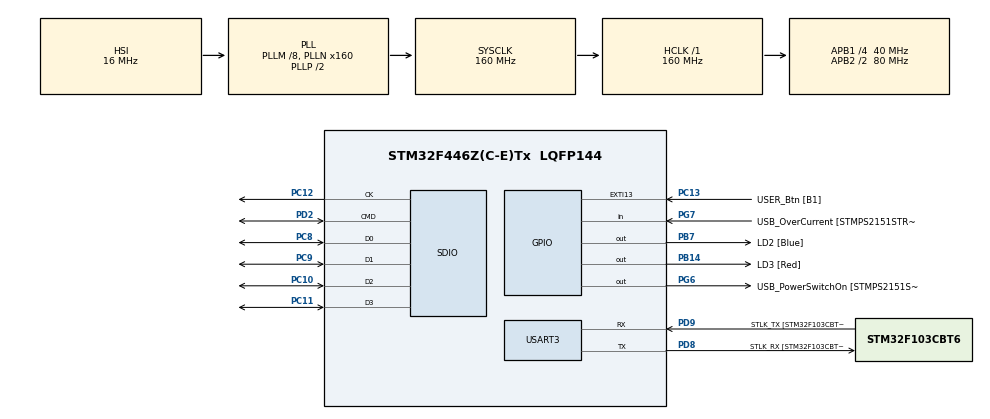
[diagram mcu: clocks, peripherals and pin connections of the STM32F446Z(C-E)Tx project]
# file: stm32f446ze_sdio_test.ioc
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Dma.Request0=SDIO_RX
Dma.Request1=SDIO_TX
Dma.SDIO_RX.0.Direction=DMA_PERIPH_TO_MEMORY
Dma.SDIO_RX.0.FIFOMode=DMA_FIFOMODE_ENABLE
Dma.SDIO_RX.0.FIFOThreshold=DMA_FIFO_THRESHOLD_FULL
Dma.SDIO_RX.0.Instance=DMA2_Stream3
Dma.SDIO_RX.0.MemBurst=DMA_MBURST_INC4
Dma.SDIO_RX.0.MemDataAlignment=DMA_MDATAALIGN_WORD
Dma.SDIO_RX.0.MemInc=DMA_MINC_ENABLE
Dma.SDIO_RX.0.Mode=DMA_PFCTRL
Dma.SDIO_RX.0.PeriphBurst=DMA_PBURST_INC4
Dma.SDIO_RX.0.PeriphDataAlignment=DMA_PDATAALIGN_WORD
Dma.SDIO_RX.0.PeriphInc=DMA_PINC_DISABLE
Dma.SDIO_RX.0.Priority=DMA_PRIORITY_LOW
Dma.SDIO_TX.1.Direction=DMA_MEMORY_TO_PERIPH
Dma.SDIO_TX.1.FIFOMode=DMA_FIFOMODE_ENABLE
Dma.SDIO_TX.1.FIFOThreshold=DMA_FIFO_THRESHOLD_FULL
Dma.SDIO_TX.1.Instance=DMA2_Stream6
Dma.SDIO_TX.1.MemBurst=DMA_MBURST_INC4
Dma.SDIO_TX.1.MemDataAlignment=DMA_MDATAALIGN_WORD
Dma.SDIO_TX.1.MemInc=DMA_MINC_ENABLE
Dma.SDIO_TX.1.Mode=DMA_PFCTRL
Dma.SDIO_TX.1.PeriphBurst=DMA_PBURST_INC4
Dma.SDIO_TX.1.PeriphDataAlignment=DMA_PDATAALIGN_WORD
Dma.SDIO_TX.1.PeriphInc=DMA_PINC_DISABLE
Dma.SDIO_TX.1.Priority=DMA_PRIORITY_LOW
Mcu.Family=STM32F4
Mcu.Name=STM32F446Z(C-E)Tx
Mcu.Package=LQFP144
NVIC.DMA2_Stream3_IRQn=true\:0\:0\:false\:false\:true\:false
NVIC.DMA2_Stream6_IRQn=true\:0\:0\:false\:false\:true\:false
NVIC.PriorityGroup=NVIC_PRIORITYGROUP_4
NVIC.SDIO_IRQn=true\:0\:0\:false\:false\:true\:true
PA10.GPIO_Label=USB_ID
PA10.Signal=USB_OTG_FS_ID
PA11.GPIO_Label=USB_DM
PA11.Signal=USB_OTG_FS_DM
PA12.GPIO_Label=USB_DP
PA12.Signal=USB_OTG_FS_DP
PA13.GPIO_Label=TMS
PA13.Signal=SYS_JTMS-SWDIO
PA14.GPIO_Label=TCK
PA14.Signal=SYS_JTCK-SWCLK
PA8.GPIO_Label=USB_SOF [TP1]
PA8.Signal=USB_OTG_FS_SOF
PA9.GPIO_Label=USB_VBUS
PA9.Signal=USB_OTG_FS_VBUS
PB14.GPIO_Label=LD3 [Red]
PB14.Signal=GPIO_Output
PB7.GPIO_Label=LD2 [Blue]
PB7.Signal=GPIO_Output
PC10.GPIO_PuPd=GPIO_PULLUP
PC10.Mode=SD_4_bits_Wide_bus
PC10.Signal=SDIO_D2
PC11.GPIO_PuPd=GPIO_PULLUP
PC11.Mode=SD_4_bits_Wide_bus
PC11.Signal=SDIO_D3
PC12.Mode=SD_4_bits_Wide_bus
PC12.Signal=SDIO_CK
PC13.GPIO_Label=USER_Btn [B1]
PC13.Signal=GPXTI13
PC14-OSC32_IN.Signal=RCC_OSC32_IN
PC15-OSC32_OUT.Signal=RCC_OSC32_OUT
PC8.GPIO_PuPd=GPIO_PULLUP
PC8.Mode=SD_4_bits_Wide_bus
PC8.Signal=SDIO_D0
PC9.GPIO_PuPd=GPIO_PULLUP
PC9.Mode=SD_4_bits_Wide_bus
PC9.Signal=SDIO_D1
PD2.GPIO_PuPd=GPIO_PULLUP
PD2.Mode=SD_4_bits_Wide_bus
PD2.Signal=SDIO_CMD
PD8.GPIO_Label=STLK_RX [STM32F103CBT6_PA3]
PD8.Mode=Asynchronous
PD8.Signal=USART3_TX
PD9.GPIO_Label=STLK_TX [STM32F103CBT6_PA2]
PD9.Mode=Asynchronous
PD9.Signal=USART3_RX
PG6.GPIO_Label=USB_PowerSwitchOn [STMPS2151STR_EN]
PG6.Signal=GPIO_Output
PG7.GPIO_Label=USB_OverCurrent [STMPS2151STR_FAULT]
PG7.Signal=GPIO_Input
PH0-OSC_IN.GPIO_Label=MCO [STM32F103CBT6_PA8]
PH0-OSC_IN.Signal=RCC_OSC_IN
PH1-OSC_OUT.Signal=RCC_OSC_OUT
ProjectManager.HeapSize=0x200
ProjectManager.StackSize=0x400
ProjectManager.TargetToolchain=MDK-ARM V5
RCC.48MHZClocksFreq_Value=24000000
RCC.AHBFreq_Value=160000000
RCC.APB1CLKDivider=RCC_HCLK_DIV4
RCC.APB1Freq_Value=40000000
RCC.APB1TimFreq_Value=80000000
RCC.APB2CLKDivider=RCC_HCLK_DIV2
RCC.APB2Freq_Value=80000000
RCC.APB2TimFreq_Value=160000000
RCC.CortexFreq_Value=160000000
RCC.HCLKFreq_Value=160000000
RCC.HSE_VALUE=8000000
RCC.HSI_VALUE=16000000
RCC.LSE_VALUE=32768
RCC.PLLM=8
RCC.PLLMUL=RCC_PLL_MUL9
RCC.PLLN=160
RCC.PLLQ=8
RCC.PRESCALERUSB=RCC_USBCLKSOURCE_PLL_DIV1_5
RCC.SYSCLKFreq_VALUE=160000000
RCC.SYSCLKSource=RCC_SYSCLKSOURCE_PLLCLK
RCC.SYSCLKSourceVirtual=RCC_SYSCLKSOURCE_PLLCLK
RCC.USBFreq_Value=40000000
RCC.VCOOutputFreq_Value=320000000
USART3.VirtualMode=VM_ASYNC
VP_FATFS_VS_SDIO.Mode=SDIO
board=NUCLEO-F446ZE

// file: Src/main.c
/**
  ******************************************************************************
  * @file           : main.c
  * @brief          : Main program body
  ******************************************************************************
  * This notice applies to any and all portions of this file
  * that are not between comment pairs USER CODE BEGIN and
  * USER CODE END. Other portions of this file, whether
  * inserted by the user or by software development tools
  * are owned by their respective copyright owners.
  *
  * Copyright (c) 2018 STMicroelectronics International N.V.
  * All rights reserved.
  *
  * Redistribution and use in source and binary forms, with or without
  * modification, are permitted, provided that the following conditions are met:
  *
  * 1. Redistribution of source code must retain the above copyright notice,
  *    this list of conditions and the following disclaimer.
  * 2. Redistributions in binary form must reproduce the above copyright notice,
  *    this list of conditions and the following disclaimer in the documentation
  *    and/or other materials provided with the distribution.
  * 3. Neither the name of STMicroelectronics nor the names of other
  *    contributors to this software may be used to endorse or promote products
  *    derived from this software without specific written permission.
  * 4. This software, including modifications and/or derivative works of this
  *    software, must execute solely and exclusively on microcontroller or
  *    microprocessor devices manufactured by or for STMicroelectronics.
  * 5. Redistribution and use of this software other than as permitted under
  *    this license is void and will automatically terminate your rights under
  *    this license.
  *
  * THIS SOFTWARE IS PROVIDED BY STMICROELECTRONICS AND CONTRIBUTORS "AS IS"
  * AND ANY EXPRESS, IMPLIED OR STATUTORY WARRANTIES, INCLUDING, BUT NOT
  * LIMITED TO, THE IMPLIED WARRANTIES OF MERCHANTABILITY, FITNESS FOR A
  * PARTICULAR PURPOSE AND NON-INFRINGEMENT OF THIRD PARTY INTELLECTUAL PROPERTY
  * RIGHTS ARE DISCLAIMED TO THE FULLEST EXTENT PERMITTED BY LAW. IN NO EVENT
  * SHALL STMICROELECTRONICS OR CONTRIBUTORS BE LIABLE FOR ANY DIRECT, INDIRECT,
  * INCIDENTAL, SPECIAL, EXEMPLARY, OR CONSEQUENTIAL DAMAGES (INCLUDING, BUT NOT
  * LIMITED TO, PROCUREMENT OF SUBSTITUTE GOODS OR SERVICES; LOSS OF USE, DATA,
  * OR PROFITS; OR BUSINESS INTERRUPTION) HOWEVER CAUSED AND ON ANY THEORY OF
  * LIABILITY, WHETHER IN CONTRACT, STRICT LIABILITY, OR TORT (INCLUDING
  * NEGLIGENCE OR OTHERWISE) ARISING IN ANY WAY OUT OF THE USE OF THIS SOFTWARE,
  * EVEN IF ADVISED OF THE POSSIBILITY OF SUCH DAMAGE.
  *
  ******************************************************************************
  */
#include "main.h"
#include "stm32f4xx_hal.h"
#include "fatfs.h"

SD_HandleTypeDef hsd;
DMA_HandleTypeDef hdma_sdio_rx;
DMA_HandleTypeDef hdma_sdio_tx;

UART_HandleTypeDef huart3;

/* USER CODE BEGIN PV */
/* Private variables ---------------------------------------------------------*/

/* USER CODE END PV */

void SystemClock_Config(void);
static void MX_GPIO_Init(void);
static void MX_DMA_Init(void);
static void MX_SDIO_SD_Init(void);
static void MX_USART3_UART_Init(void);

/* USER CODE BEGIN PFP */
/* Private function prototypes -----------------------------------------------*/

/* USER CODE END PFP */

int main(void)
{

  /* MCU Configuration----------------------------------------------------------*/

  /* Reset of all peripherals, Initializes the Flash interface and the Systick. */
  HAL_Init();

  /* Configure the system clock */
  SystemClock_Config();

  /* Initialize all configured peripherals */
  MX_GPIO_Init();
  MX_DMA_Init();
  MX_SDIO_SD_Init();
  MX_FATFS_Init();
  MX_USART3_UART_Init();
  /* USER CODE BEGIN 2 */

	FIL MyFile;
	FRESULT res =  f_mount(&SDFatFS, (TCHAR const*)SDPath, 0);
	res = f_open(&MyFile, "config.txt", FA_READ | FA_OPEN_EXISTING);

	if(res != FR_OK){
		printf("Open Error: %d\r\n", res);
	}

  /* USER CODE END 2 */

  /* Infinite loop */
  while (1)
  {

  }

}

void SystemClock_Config(void)
{

  RCC_OscInitTypeDef RCC_OscInitStruct;
  RCC_ClkInitTypeDef RCC_ClkInitStruct;
  RCC_PeriphCLKInitTypeDef PeriphClkInitStruct;

    /**Configure the main internal regulator output voltage
    */
  __HAL_RCC_PWR_CLK_ENABLE();

  __HAL_PWR_VOLTAGESCALING_CONFIG(PWR_REGULATOR_VOLTAGE_SCALE1);

    /**Initializes the CPU, AHB and APB busses clocks
    */
  RCC_OscInitStruct.OscillatorType = RCC_OSCILLATORTYPE_HSI;
  RCC_OscInitStruct.HSIState = RCC_HSI_ON;
  RCC_OscInitStruct.HSICalibrationValue = 16;
  RCC_OscInitStruct.PLL.PLLState = RCC_PLL_ON;
  RCC_OscInitStruct.PLL.PLLSource = RCC_PLLSOURCE_HSI;
  RCC_OscInitStruct.PLL.PLLM = 8;
  RCC_OscInitStruct.PLL.PLLN = 160;
  RCC_OscInitStruct.PLL.PLLP = RCC_PLLP_DIV2;
  RCC_OscInitStruct.PLL.PLLQ = 8;
  RCC_OscInitStruct.PLL.PLLR = 2;
  if (HAL_RCC_OscConfig(&RCC_OscInitStruct) != HAL_OK)
  {
    _Error_Handler(__FILE__, __LINE__);
  }

    /**Initializes the CPU, AHB and APB busses clocks
    */
  RCC_ClkInitStruct.ClockType = RCC_CLOCKTYPE_HCLK|RCC_CLOCKTYPE_SYSCLK
                              |RCC_CLOCKTYPE_PCLK1|RCC_CLOCKTYPE_PCLK2;
  RCC_ClkInitStruct.SYSCLKSource = RCC_SYSCLKSOURCE_PLLCLK;
  RCC_ClkInitStruct.AHBCLKDivider = RCC_SYSCLK_DIV1;
  RCC_ClkInitStruct.APB1CLKDivider = RCC_HCLK_DIV4;
  RCC_ClkInitStruct.APB2CLKDivider = RCC_HCLK_DIV2;

  if (HAL_RCC_ClockConfig(&RCC_ClkInitStruct, FLASH_LATENCY_5) != HAL_OK)
  {
    _Error_Handler(__FILE__, __LINE__);
  }

  PeriphClkInitStruct.PeriphClockSelection = RCC_PERIPHCLK_SDIO|RCC_PERIPHCLK_CLK48;
  PeriphClkInitStruct.Clk48ClockSelection = RCC_CLK48CLKSOURCE_PLLQ;
  PeriphClkInitStruct.SdioClockSelection = RCC_SDIOCLKSOURCE_CLK48;
  if (HAL_RCCEx_PeriphCLKConfig(&PeriphClkInitStruct) != HAL_OK)
  {
    _Error_Handler(__FILE__, __LINE__);
  }

    /**Configure the Systick interrupt time
    */
  HAL_SYSTICK_Config(HAL_RCC_GetHCLKFreq()/1000);

    /**Configure the Systick
    */
  HAL_SYSTICK_CLKSourceConfig(SYSTICK_CLKSOURCE_HCLK);

  /* SysTick_IRQn interrupt configuration */
  HAL_NVIC_SetPriority(SysTick_IRQn, 0, 0);
}

/* SDIO init function */
static void MX_SDIO_SD_Init(void)
{

  hsd.Instance = SDIO;
  hsd.Init.ClockEdge = SDIO_CLOCK_EDGE_RISING;
  hsd.Init.ClockBypass = SDIO_CLOCK_BYPASS_DISABLE;
  hsd.Init.ClockPowerSave = SDIO_CLOCK_POWER_SAVE_DISABLE;
  hsd.Init.BusWide = SDIO_BUS_WIDE_1B;
  hsd.Init.HardwareFlowControl = SDIO_HARDWARE_FLOW_CONTROL_DISABLE;
  hsd.Init.ClockDiv = 0;

}

/* USART3 init function */
static void MX_USART3_UART_Init(void)
{

  huart3.Instance = USART3;
  huart3.Init.BaudRate = 115200;
  huart3.Init.WordLength = UART_WORDLENGTH_8B;
  huart3.Init.StopBits = UART_STOPBITS_1;
  huart3.Init.Parity = UART_PARITY_NONE;
  huart3.Init.Mode = UART_MODE_TX_RX;
  huart3.Init.HwFlowCtl = UART_HWCONTROL_NONE;
  huart3.Init.OverSampling = UART_OVERSAMPLING_16;
  if (HAL_UART_Init(&huart3) != HAL_OK)
  {
    _Error_Handler(__FILE__, __LINE__);
  }

}

static void MX_DMA_Init(void)
{
  /* DMA controller clock enable */
  __HAL_RCC_DMA2_CLK_ENABLE();

  /* DMA interrupt init */
  /* DMA2_Stream3_IRQn interrupt configuration */
  HAL_NVIC_SetPriority(DMA2_Stream3_IRQn, 0, 0);
  HAL_NVIC_EnableIRQ(DMA2_Stream3_IRQn);
  /* DMA2_Stream6_IRQn interrupt configuration */
  HAL_NVIC_SetPriority(DMA2_Stream6_IRQn, 0, 0);
  HAL_NVIC_EnableIRQ(DMA2_Stream6_IRQn);

}

/** Configure pins as
        * Analog
        * Input
        * Output
        * EVENT_OUT
        * EXTI
     PA8   ------> USB_OTG_FS_SOF
     PA9   ------> USB_OTG_FS_VBUS
     PA10   ------> USB_OTG_FS_ID
     PA11   ------> USB_OTG_FS_DM
     PA12   ------> USB_OTG_FS_DP
*/
static void MX_GPIO_Init(void)
{

  GPIO_InitTypeDef GPIO_InitStruct;

  /* GPIO Ports Clock Enable */
  __HAL_RCC_GPIOC_CLK_ENABLE();
  __HAL_RCC_GPIOH_CLK_ENABLE();
  __HAL_RCC_GPIOB_CLK_ENABLE();
  __HAL_RCC_GPIOD_CLK_ENABLE();
  __HAL_RCC_GPIOG_CLK_ENABLE();
  __HAL_RCC_GPIOA_CLK_ENABLE();

  /*Configure GPIO pin Output Level */
  HAL_GPIO_WritePin(GPIOB, LD3_Pin|LD2_Pin, GPIO_PIN_RESET);

  /*Configure GPIO pin Output Level */
  HAL_GPIO_WritePin(USB_PowerSwitchOn_GPIO_Port, USB_PowerSwitchOn_Pin, GPIO_PIN_RESET);

  /*Configure GPIO pin : USER_Btn_Pin */
  GPIO_InitStruct.Pin = USER_Btn_Pin;
  GPIO_InitStruct.Mode = GPIO_MODE_IT_RISING;
  GPIO_InitStruct.Pull = GPIO_NOPULL;
  HAL_GPIO_Init(USER_Btn_GPIO_Port, &GPIO_InitStruct);

  /*Configure GPIO pins : LD3_Pin LD2_Pin */
  GPIO_InitStruct.Pin = LD3_Pin|LD2_Pin;
  GPIO_InitStruct.Mode = GPIO_MODE_OUTPUT_PP;
  GPIO_InitStruct.Pull = GPIO_NOPULL;
  GPIO_InitStruct.Speed = GPIO_SPEED_FREQ_LOW;
  HAL_GPIO_Init(GPIOB, &GPIO_InitStruct);

  /*Configure GPIO pin : USB_PowerSwitchOn_Pin */
  GPIO_InitStruct.Pin = USB_PowerSwitchOn_Pin;
  GPIO_InitStruct.Mode = GPIO_MODE_OUTPUT_PP;
  GPIO_InitStruct.Pull = GPIO_NOPULL;
  GPIO_InitStruct.Speed = GPIO_SPEED_FREQ_LOW;
  HAL_GPIO_Init(USB_PowerSwitchOn_GPIO_Port, &GPIO_InitStruct);

  /*Configure GPIO pin : USB_OverCurrent_Pin */
  GPIO_InitStruct.Pin = USB_OverCurrent_Pin;
  GPIO_InitStruct.Mode = GPIO_MODE_INPUT;
  GPIO_InitStruct.Pull = GPIO_NOPULL;
  HAL_GPIO_Init(USB_OverCurrent_GPIO_Port, &GPIO_InitStruct);

  /*Configure GPIO pins : USB_SOF_Pin USB_ID_Pin USB_DM_Pin USB_DP_Pin */
  GPIO_InitStruct.Pin = USB_SOF_Pin|USB_ID_Pin|USB_DM_Pin|USB_DP_Pin;
  GPIO_InitStruct.Mode = GPIO_MODE_AF_PP;
  GPIO_InitStruct.Pull = GPIO_NOPULL;
  GPIO_InitStruct.Speed = GPIO_SPEED_FREQ_VERY_HIGH;
  GPIO_InitStruct.Alternate = GPIO_AF10_OTG_FS;
  HAL_GPIO_Init(GPIOA, &GPIO_InitStruct);

  /*Configure GPIO pin : USB_VBUS_Pin */
  GPIO_InitStruct.Pin = USB_VBUS_Pin;
  GPIO_InitStruct.Mode = GPIO_MODE_INPUT;
  GPIO_InitStruct.Pull = GPIO_NOPULL;
  HAL_GPIO_Init(USB_VBUS_GPIO_Port, &GPIO_InitStruct);

}

/* USER CODE BEGIN 4 */
int fputc(int ch, FILE *f)
//int stdout_putchar(int ch, FILE *f)
{
  HAL_UART_Transmit(&huart3, (uint8_t *)&ch, 1, 0xFFFF);
  return ch;
}
/* USER CODE END 4 */

void _Error_Handler(char *file, int line)
{
  while(1)
  {
  }
}

/************************ (C) COPYRIGHT STMicroelectronics *****END OF FILE****/
